# nrf51 register map
Vendor: Nordic Semiconductor; Series: nrf51; File version: 522
CPU: CM0 r3p1, little endian, no MPU, no FPU, 2 interrupt priority bits
Registers are 32-bit, read-write, reset 0x0 unless marked. A register's access mark holds for its fields unless they carry their own. Offsets are from the block's base; [hi:lo] are bit positions; 'fields as' and 'values as' point back to an identical list.

## UART0 — Universal Asynchronous Receiver/Transmitter.
Base 0x40002000
0x00 TASKS_STARTRX wo — Start UART receiver.
0x04 TASKS_STOPRX wo — Stop UART receiver.
0x08 TASKS_STARTTX wo — Start UART transmitter.
0x0C TASKS_STOPTX wo — Stop UART transmitter.
0x1C TASKS_SUSPEND wo — Suspend UART.
0x100 EVENTS_CTS — CTS activated.
0x104 EVENTS_NCTS — CTS deactivated.
0x108 EVENTS_RXDRDY — Data received in RXD.
0x11C EVENTS_TXDRDY — Data sent from TXD.
0x124 EVENTS_ERROR — Error detected.
0x144 EVENTS_RXTO — Receiver timeout.
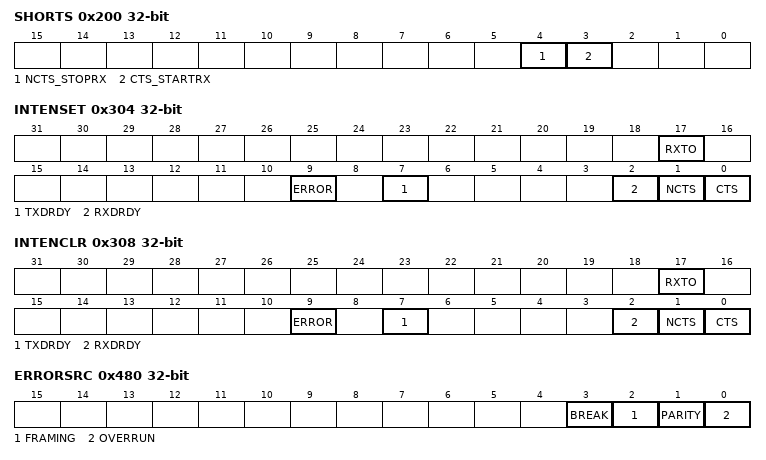
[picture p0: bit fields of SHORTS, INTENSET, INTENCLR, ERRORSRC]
0x200 SHORTS — Shortcuts for UART.
  [4] NCTS_STOPRX — Shortcut between NCTS event and STOPRX task.
    0=Disabled (Shortcut disabled.); 1=Enabled (Shortcut enabled.)
  [3] CTS_STARTRX — Shortcut between CTS event and STARTRX task.
    values as NCTS_STOPRX
0x304 INTENSET — Interrupt enable set register.
  [all] fields
    on read: 0=Disabled (Interrupt disabled.); 1=Enabled (Interrupt enabled.) | on write: 1=Set (Enable interrupt on write.)
  [17] RXTO — Enable interrupt on RXTO event.
  [9] ERROR — Enable interrupt on ERROR event.
  [7] TXDRDY — Enable interrupt on TXRDY event.
  [2] RXDRDY — Enable interrupt on RXRDY event.
  [1] NCTS — Enable interrupt on NCTS event.
  [0] CTS — Enable interrupt on CTS event.
0x308 INTENCLR — Interrupt enable clear register.
  [all] fields
    on read: 0=Disabled (Interrupt disabled.); 1=Enabled (Interrupt enabled.) | on write: 1=Clear (Disable interrupt on write.)
  [17] RXTO — Disable interrupt on RXTO event.
  [9] ERROR — Disable interrupt on ERROR event.
  [7] TXDRDY — Disable interrupt on TXRDY event.
  [2] RXDRDY — Disable interrupt on RXRDY event.
  [1] NCTS — Disable interrupt on NCTS event.
  [0] CTS — Disable interrupt on CTS event.
0x480 ERRORSRC — Error source. Write error field to 1 to clear error.
  [all] fields
    on read: 0=NotPresent (Error not present.); 1=Present (Error present.) | on write: 1=Clear error on write
  [3] BREAK — The serial data input is '0' for longer than the length of a data frame.
  [2] FRAMING — A valid stop bit is not detected on the serial data input after all bits in a character have been received.
  [1] PARITY — A character with bad parity is received. Only checked if HW parity control is enabled.
  [0] OVERRUN — A start bit is received while the previous data still lies in RXD. (Data loss).
0x500 ENABLE — Enable UART and acquire IOs.
  [2:0] ENABLE — Enable or disable UART and acquire IOs.
    0=Disabled (UART disabled.); 4=Enabled (UART enabled.)
0x508 PSELRTS reset 0xFFFFFFFF — Pin select for RTS.
0x50C PSELTXD reset 0xFFFFFFFF — Pin select for TXD.
0x510 PSELCTS reset 0xFFFFFFFF — Pin select for CTS.
0x514 PSELRXD reset 0xFFFFFFFF — Pin select for RXD.
0x518 RXD ro read-has-side-effects — RXD register. On read action the buffer pointer is displaced. Once read the character is consumed. If read when no character available, the UART will stop working.
  [7:0] RXD — RX data from previous transfer. Double buffered.
0x51C TXD wo
  [7:0] TXD — TX data for transfer.
0x524 BAUDRATE — UART Baudrate.
  [31:0] BAUDRATE — UART baudrate.
    0x4F000=Baud1200 (1200 baud.); 0x9D000=Baud2400 (2400 baud.); 0x13B000=Baud4800 (4800 baud.); 0x275000=Baud9600 (9600 baud.); 0x3B0000=Baud14400 (14400 baud.); 0x4EA000=Baud19200 (19200 baud.); 0x75F000=Baud28800 (28800 baud.); 0x800000=Baud31250 (31250 baud.); 0x9D5000=Baud38400 (38400 baud.); 0xE50000=Baud56000 (56000 baud.); 0xEBF000=Baud57600 (57600 baud.); 0x13A9000=Baud76800 (76800 baud.); 0x1D7E000=Baud115200 (115200 baud.); 0x3AFB000=Baud230400 (230400 baud.); 0x4000000=Baud250000 (250000 baud.); 0x75F7000=Baud460800 (460800 baud.); 0xEBED000=Baud921600 (921600 baud.); 0x10000000=Baud1M (1M baud.)
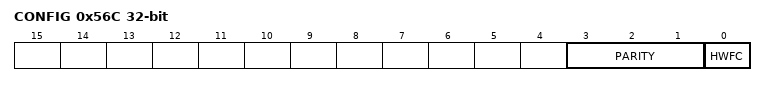
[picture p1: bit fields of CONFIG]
0x56C CONFIG — Configuration of parity and hardware flow control register.
  [3:1] PARITY — Include parity bit.
    0=Excluded (Parity bit excluded.); 7=Included (Parity bit included.)
  [0] HWFC — Hardware flow control.
    0=Disabled (Hardware flow control disabled.); 1=Enabled (Hardware flow control enabled.)
0xFFC POWER — Peripheral power control.
  [0] POWER
    0=Disabled (Module power disabled.); 1=Enabled (Module power enabled.)
